# SGPIO1 register map
Registers from a debugger description file.
Registers are 32-bit, access not given, no defined reset value unless marked. A register's access mark holds for its fields unless they carry their own. Addresses are absolute; registers are grouped by the start of their names; lines under a group give offsets from that group; [hi:lo] are bit positions; {n}, {i} and the like mark numbered series; 'fields as' and 'values as' point back to an identical list; <NAME> marks a mode.

## SGPIO1
0x4006D000 SGPIO1/Input ro
  [31:0] Input
0x4006D004 SGPIO1/Output
  [31:0] Output
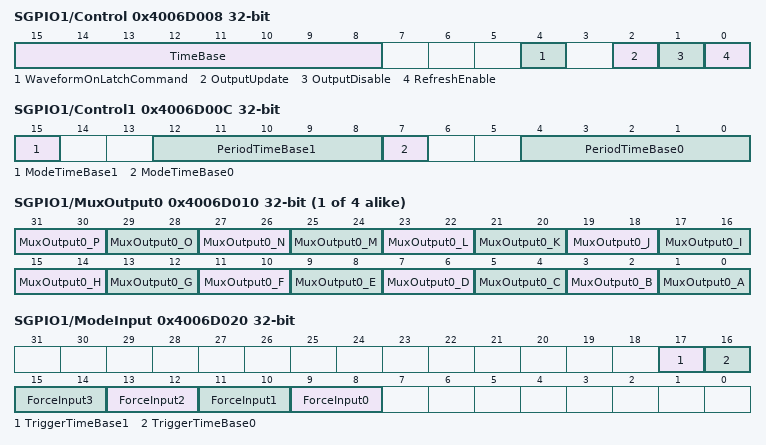
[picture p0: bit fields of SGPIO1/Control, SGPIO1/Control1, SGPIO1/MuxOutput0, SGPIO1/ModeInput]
0x4006D008 SGPIO1/Control
  [15:8] TimeBase, [4] WaveformOnLatchCommand, [2] OutputUpdate, [1] OutputDisable, [0] RefreshEnable
0x4006D00C SGPIO1/Control1
  [15] ModeTimeBase1, [12:8] PeriodTimeBase1, [7] ModeTimeBase0, [4:0] PeriodTimeBase0
{0x4006D010+4i} SGPIO1/MuxOutput{i} (i=0..3)
  [31:30] MuxOutput{i}_P, [29:28] MuxOutput{i}_O, [27:26] MuxOutput{i}_N, [25:24] MuxOutput{i}_M, [23:22] MuxOutput{i}_L, [21:20] MuxOutput{i}_K, [19:18] MuxOutput{i}_J, [17:16] MuxOutput{i}_I, [15:14] MuxOutput{i}_H, [13:12] MuxOutput{i}_G, [11:10] MuxOutput{i}_F, [9:8] MuxOutput{i}_E, [7:6] MuxOutput{i}_D, [5:4] MuxOutput{i}_C, [3:2] MuxOutput{i}_B, [1:0] MuxOutput{i}_A
0x4006D020 SGPIO1/ModeInput
  [17] TriggerTimeBase1, [16] TriggerTimeBase0, [2n+9:2n+8] ForceInput{n} (n=0..3)
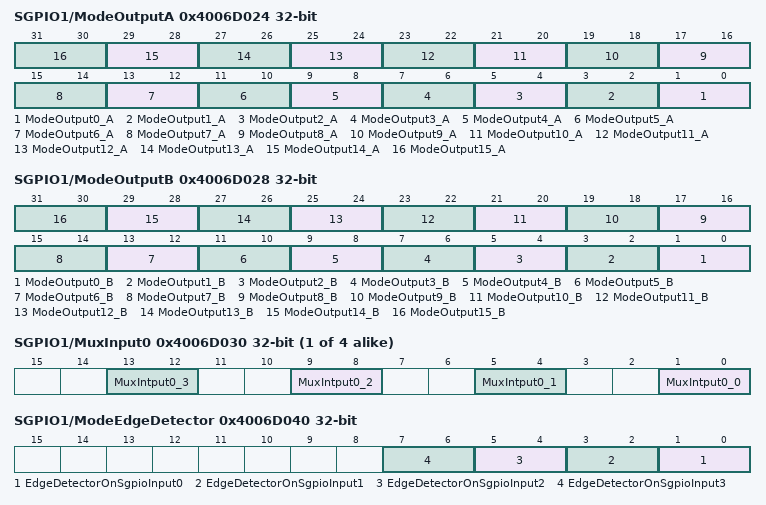
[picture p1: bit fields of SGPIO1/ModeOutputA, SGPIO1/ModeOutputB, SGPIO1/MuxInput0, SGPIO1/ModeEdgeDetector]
0x4006D024 SGPIO1/ModeOutputA
  [2n+1:2n] ModeOutput{n}_A (n=0..15)
0x4006D028 SGPIO1/ModeOutputB
  [2n+1:2n] ModeOutput{n}_B (n=0..15)
{0x4006D030+4i} SGPIO1/MuxInput{i} (i=0..3)
  [4n+1:4n] MuxIntput{i}_{n} (n=0..3)
0x4006D040 SGPIO1/ModeEdgeDetector
  [2n+1:2n] EdgeDetectorOnSgpioInput{n} (n=0..3)
0x4006D044 SGPIO1/StatusInt0
  [3:0] StatusInt0
0x4006D048 SGPIO1/StatusInt1
  [3:0] StatusInt1
0x4006D04C SGPIO1/MaskInt
  [3:0] MaskInt
0x4006D050 SGPIO1/ClearInt
  [3:0] ClearInt
0x4006D054 SGPIO1/InputUpdate
  [31:0] InputUpdate
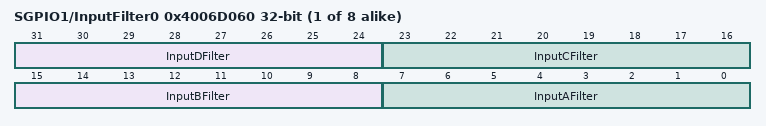
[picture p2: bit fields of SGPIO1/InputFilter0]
{0x4006D060+4i} SGPIO1/InputFilter{i} (i=0..7)
  [31:24] InputDFilter, [23:16] InputCFilter, [15:8] InputBFilter, [7:0] InputAFilter
